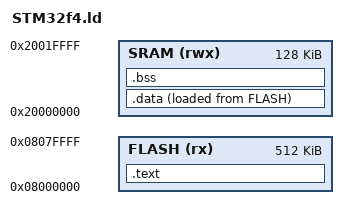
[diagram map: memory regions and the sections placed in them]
/* Entry point */
ENTRY(Reset_Handler)

/* Memory definition */
MEMORY
{
    FLASH (rx)  : ORIGIN = 0x08000000, LENGTH = 512K
    SRAM  (rwx) : ORIGIN = 0x20000000, LENGTH = 128K
}

/* Top of stack */
_estack = ORIGIN(SRAM) + LENGTH(SRAM);

/* Sections */
SECTIONS
{
    /* ===== TEXT ===== */
    .text :
    {
        . = ALIGN(4);
        KEEP(*(.isr_vector))
        *(.text*)
        *(.rodata*)
        . = ALIGN(4);
        _etext = .;
    } > FLASH

    /* ===== DATA ===== */
    .data :
    {
        . = ALIGN(4);
        _sdata = .;
        *(.data*)
        . = ALIGN(4);
        _edata = .;
    } > SRAM AT > FLASH

    _sidata = LOADADDR(.data);

    /* ===== BSS ===== */
    .bss :
    {
        . = ALIGN(4);
        _sbss = .;
        __bss_start__ = .;
        *(.bss*)
        *(COMMON)
        . = ALIGN(4);
        _ebss = .;
        __bss_end__ = .;
    } > SRAM

    /* Requerido por _sbrk de libnosys */
    end  = .;
    _end = .;
}
